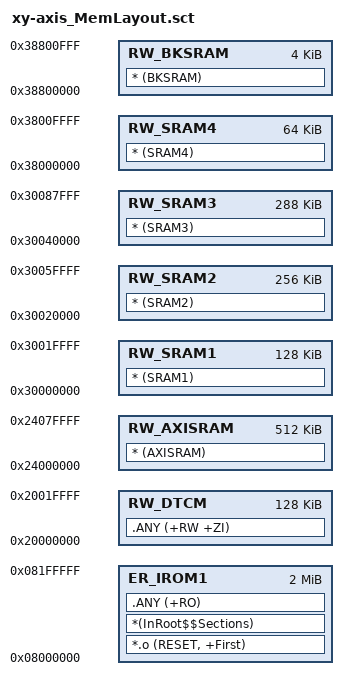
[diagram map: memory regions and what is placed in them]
; *************************************************************
; *** Scatter-Loading Description File generated by uVision ***
; *************************************************************

LR_IROM1 0x08000000 0x00200000  {    ; load region size_region
  ER_IROM1 0x08000000 0x00200000  {  ; load address = execution address
   *.o (RESET, +First)
   *(InRoot$$Sections)
   .ANY (+RO)
  }

; RW data - 128KB DTCM
  RW_DTCM 0x20000000 0x00020000  {  ; RW data
   .ANY (+RW +ZI)
  }

; RW data - 512KB AXI SRAM
  RW_AXISRAM 0x24000000 0x00080000  {  ; RW data
   * (AXISRAM)
  }

; RW data - 128KB SRAM1
  RW_SRAM1 0x30000000 0x00020000  {  ; RW data
   * (SRAM1)
  }

; RW data - 256KB SRAM2
  RW_SRAM2 0x30020000 0x00040000  {  ; RW data
   * (SRAM2)
  }

; RW data - 288KB SRAM3
  RW_SRAM3 0x30040000 0x00048000  {  ; RW data
   * (SRAM3)
  }

; RW data - 64KB SRAM4
  RW_SRAM4 0x38000000 0x00010000  {  ; RW data
   * (SRAM4)
  }

; RW data - 4KB BACKUP SRAM
  RW_BKSRAM 0x38800000 0x00001000  {  ; RW data
   * (BKSRAM)
  }

}

